# MCXC444 register map
Vendor: NXP Semiconductors; Series: MCX; File version: 1.6
CPU: CM0PLUS r0p0, little endian, no MPU, no FPU, VTOR, 2 interrupt priority bits
Registers are 32-bit, read-write, reset 0x0 unless marked. A register's access mark holds for its fields unless they carry their own. Offsets are from the block's base; [hi:lo] are bit positions; 'fields as' and 'values as' point back to an identical list.

## MCG — Multipurpose Clock Generator Lite
Base 0x40064000; register names take the prefix MCG_
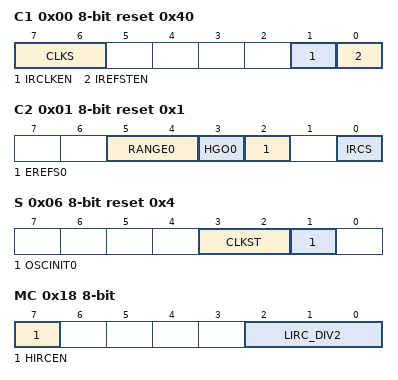
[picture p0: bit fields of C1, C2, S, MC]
0x00 C1 8-bit reset 0x40 — MCG Control Register 1
  [7:6] CLKS — Clock Source Select
    0=b00 (Selects HIRC clock as the main clock source. This is HIRC mode.); 1=b01 (Selects LIRC clock as the main clock source. This is LIRC2M or LIRC8M mode.); 2=b10 (Selects external clock as the main clock source. This is EXT mode.); 3=b11 (Reserved. Writing 11 takes no effect.)
  [1] IRCLKEN — Internal Reference Clock Enable
    0=b0 (LIRC is disabled.); 1=b1 (LIRC is enabled.)
  [0] IREFSTEN — Internal Reference Stop Enable
    0=b0 (LIRC is disabled in Stop mode.); 1=b1 (LIRC is enabled in Stop mode, if IRCLKEN is set.)
0x01 C2 8-bit reset 0x1 — MCG Control Register 2
  [5:4] RANGE0 — External Clock Source Frequency Range Select
    0=b00 (Low frequency range selected for the crystal oscillator or the external clock source.); 1=b01 (High frequency range selected for the crystal oscillator or the external clock source.); 2=b10 (Very high frequency range selected for the crystal oscillator or the external clock source.); 3=b11 (Very high frequency range selected for the crystal oscillator or the external clock source. Same effect as 10.)
  [3] HGO0 — Crystal Oscillator Operation Mode Select
    0=b0 (Configure crystal oscillator for low-power operation.); 1=b1 (Configure crystal oscillator for high-gain operation.)
  [2] EREFS0 — External Clock Source Select
    0=b0 (External clock requested.); 1=b1 (Oscillator requested.)
  [0] IRCS — Low-frequency Internal Reference Clock Select
    0=b0 (LIRC is in 2 MHz mode.); 1=b1 (LIRC is in 8 MHz mode.)
0x06 S 8-bit ro reset 0x4 — MCG Status Register
  [3:2] CLKST — Clock Mode Status
    0=b00 (HIRC clock is selected as the main clock source, and MCG_Lite works at HIRC mode.); 1=b01 (LIRC clock is selected as the main clock source, and MCG_Lite works at LIRC2M or LIRC8M mode.); 2=b10 (External clock is selected as the main clock source, and MCG_Lite works at EXT mode.)
  [1] OSCINIT0 — OSC Initialization Status
    0=b0 (OSC is not ready.); 1=b1 (OSC clock is ready.)
0x08 SC 8-bit — MCG Status and Control Register
  [3:1] FCRDIV — Low-frequency Internal Reference Clock Divider
    0=b000 (Division factor is 1.); 1=b001 (Division factor is 2.); 2=b010 (Division factor is 4.); 3=b011 (Division factor is 8.); 4=b100 (Division factor is 16.); 5=b101 (Division factor is 32.); 6=b110 (Division factor is 64.); 7=b111 (Division factor is 128.)
0x14 HCTRIM 8-bit ro reset not defined — MCG High-frequency IRC Coarse Trim Register
  [5:0] COARSE_TRIM — High-frequency IRC Coarse Trim
0x15 HTTRIM 8-bit ro reset not defined — MCG High-frequency IRC Tempco (Temperature Coefficient) Trim Register
  [4:0] TEMPCO_TRIM — High-frequency IRC Tempco Trim
0x16 HFTRIM 8-bit ro reset not defined — MCG High-frequency IRC Fine Trim Register
  [6:0] FINE_TRIM — High-frequency IRC Fine Trim
0x18 MC 8-bit — MCG Miscellaneous Control Register
  [7] HIRCEN — High-frequency IRC Enable
    0=b0 (HIRC source is not enabled.); 1=b1 (HIRC source is enabled.)
  [2:0] LIRC_DIV2 — Second Low-frequency Internal Reference Clock Divider
    values as SC.FCRDIV
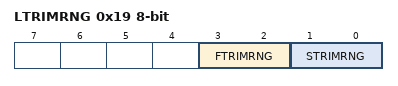
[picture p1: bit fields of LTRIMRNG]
0x19 LTRIMRNG 8-bit ro reset not defined — MCG Low-frequency IRC Trim Range Register
  [3:2] FTRIMRNG — LIRC Fast TRIM (8 MHz) Range
    0=b00 (Frequency shift by 10%.); 1=b01 (No frequency shift.); 2=b10 (No frequency shift.); 3=b11 (Frequency shift by -10%.)
  [1:0] STRIMRNG — LIRC Slow TRIM (2 MHz) Range
    values as FTRIMRNG
0x1A LFTRIM 8-bit ro reset not defined — MCG Low-frequency IRC8M Trim Register
  [6:0] LIRC_FTRIM — LIRC8M TRIM
0x1B LSTRIM 8-bit ro reset not defined — MCG Low-frequency IRC2M Trim Register
  [6:0] LIRC_STRIM — LIRC2M TRIM
